# ADuCM322i register map
Vendor: Analog Devices Inc.; Series: ARMCM3; File version: 1.0
CPU: CM3 r2p1, little endian, no MPU, no FPU, 3 interrupt priority bits
Registers are 16-bit, read-write, no defined reset value unless marked. A register's access mark holds for its fields unless they carry their own. Offsets are from the block's base; [hi:lo] are bit positions.

## WUT — Wake up Timer
Base 0x40002500
0x00 T4VAL0 ro — Current count value - LS 16 bits
  [15:0] T4VALL range 0x00000000..0x0000FFFF — Current count Low
0x04 T4VAL1 ro — Current count value - MS 16 bits
  [15:0] T4VALH range 0x00000000..0x0000FFFF — Current count high
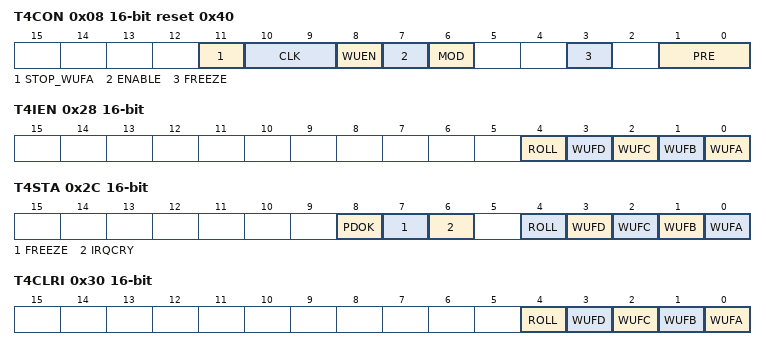
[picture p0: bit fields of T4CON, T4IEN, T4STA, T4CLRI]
0x08 T4CON reset 0x40 (reset mask 0x0) — Control register
  [11] STOP_WUFA range 0x00000000..0x00000001 — Disables updating field A register T4WUFA
  [10:9] CLK — Clock select
    0=PCLK (: PCLK (default)); 1=LFOSC (: 32 kHz internal oscillator); 3=ECLKIN (: External clock from P1.0)
  [8] WUEN — Wakeup enable
    0=DIS (: Cleared by user to disable the wake up timer when the core clock is off); 1=EN (: Set by user to enable the wake up timer even when the core clock is off.)
  [7] ENABLE — Timer enable
    0=DIS (: Disable the timer (default).); 1=EN (: Enable the timer.)
  [6] MOD — Timer mode
    0=PERIODIC (: Cleared by user to operate in periodic mode. In this mode, the timer counts up to T4WUFD); 1=FREERUN (: Set by user to operate in free running mode (default).)
  [3] FREEZE — Freeze enable
    0=DIS (: Cleared by user to disable this feature (default).); 1=EN (: Set by user to enable the freeze of the high 16-bits after the lower bits have been read from T4VAL0. This ensures that the software will read an atomic shot of the timer. T4VAL1 unfreezes after it has been read.)
  [1:0] PRE — Prescaler
    0=PREDIV1 (: source clock/1 (default). If the selected clock source is PCLK, then this setting results in a prescaler of 4.); 1=PREDIV16 (: source clock/16); 2=PREDIV256 (: source clock/256); 3=PREDIV32768 (: source clock/32,768)
0x0C T4INC reset 0xC8 (reset mask 0x0) — 12-bit interval for wakeup field A
  [11:0] INTERVAL range 0x00000000..0x00000FFF — Interval for wakeup field A
0x10 T4WUFB0 reset 0x1FFF (reset mask 0x0) — Wakeup field B - LS 16 bits
  [15:0] T4WUFBL range 0x00000000..0x0000FFFF — Wakeup field B low
0x14 T4WUFB1 — Wakeup field B - MS 16 bits
  [15:0] T4WUFBH range 0x00000000..0x0000FFFF — Wakeup field B High
0x18 T4WUFC0 reset 0x2FFF (reset mask 0x0) — Wakeup field C - LS 16 bits
  [15:0] T4WUFCL range 0x00000000..0x0000FFFF — Wakeup field C Low
0x1C T4WUFC1 — Wakeup field C - MS 16 bits
  [15:0] T4WUFCH range 0x00000000..0x0000FFFF — Wakeup field C High
0x20 T4WUFD0 reset 0x3FFF (reset mask 0x0) — Wakeup field D - LS 16 bits
  [15:0] T4WUFD0 range 0x00000000..0x0000FFFF — Wakeup field D Low
0x24 T4WUFD1 — Wakeup field D - MS 16 bits
  [15:0] T4WUFDH range 0x00000000..0x0000FFFF — Wakeup field D high
0x28 T4IEN — Interrupt enable register
  [4] ROLL range 0x00000000..0x00000001 — Rollover interrupt enable
  [3] WUFD range 0x00000000..0x00000001 — T4WUFD interrupt enable
  [2] WUFC range 0x00000000..0x00000001 — T4WUFC interrupt enable
  [1] WUFB range 0x00000000..0x00000001 — T4WUFB interrupt enable
  [0] WUFA range 0x00000000..0x00000001 — T4WUFA interrupt enable
0x2C T4STA ro — Status register
  [8] PDOK range 0x00000000..0x00000001 — Enable bit synchronized
  [7] FREEZE range 0x00000000..0x00000001 — Timer value freeze
  [6] IRQCRY range 0x00000000..0x00000001 — Wakeup status to powerdown
  [4] ROLL range 0x00000000..0x00000001 — Rollover interrupt flag
  [3] WUFD range 0x00000000..0x00000001 — T4WUFD interrupt flag
  [2] WUFC range 0x00000000..0x00000001 — T4WUFC interrupt flag
  [1] WUFB range 0x00000000..0x00000001 — T4WUFB interrupt flag
  [0] WUFA range 0x00000000..0x00000001 — T4WUFA interrupt flag
0x30 T4CLRI wo — Clear interrupt register
  [4] ROLL range 0x00000000..0x00000001 — Rollover interrupt clear
  [3] WUFD range 0x00000000..0x00000001 — T4WUFD interrupt clear
  [2] WUFC range 0x00000000..0x00000001 — T4WUFC interrupt clear
  [1] WUFB range 0x00000000..0x00000001 — T4WUFB interrupt clear
  [0] WUFA range 0x00000000..0x00000001 — T4WUFA interrupt clear
0x3C T4WUFA0 ro reset 0x1900 (reset mask 0x0) — Wakeup field A - LS 16 bits
  [15:0] T4WUFAL range 0x00000000..0x0000FFFF — Wakeup field A Low
0x40 T4WUFA1 ro — Wakeup field A - MS 16 bits
  [15:0] T4WUFAH range 0x00000000..0x0000FFFF — Wakeup field A High
